# M0519AE_v1 register map
File version: 1.0
Registers are 32-bit, read-write, reset 0x0 unless marked. A register's access mark holds for its fields unless they carry their own. Offsets are from the block's base; [hi:lo] are bit positions; {n}, {i} and the like mark numbered series.

## FMC — FMC Register Map
Base 0x5000C000
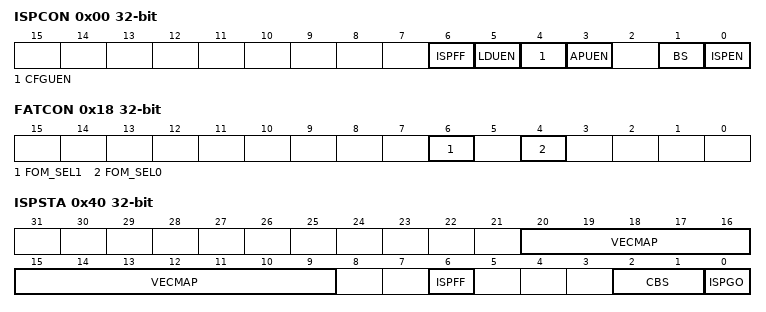
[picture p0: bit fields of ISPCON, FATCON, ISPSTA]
0x00 ISPCON (reset mask 0xFFFFFFF0) — ISP Control Register
  [6] ISPFF — ISP Fail Flag (Write Protect). This bit is set by hardware when a triggered ISP meets any of the following conditions: (1) APROM writes to itself if APUEN is set to 0. (2) LDROM writes to itself if LDUEN is set to 0. (3) CONFIG is erased/programmed if CFGUEN is set to 0. (4) Page Erase command at LOCK mode with ICE connection (5) Erase or Program command at brown-out detected (6) Destination address is illegal, such as over an available range. (7) Invalid ISP commands. Write 1 to clear this bit.
  [5] LDUEN — LDROM Update Enable Bit (Write Protect). LDROM update enable bit.
    0=LDROM cannot be updated; 1=LDROM can be updated when chip runs in APROM
  [4] CFGUEN — Config-bits Update Enable Bit (Write Protect)
    0=User Configuration cannot be updated; 1=User Configuration can be updated
  [3] APUEN — APROM Update Enable Bit (Write Protect)
    0=APROM cannot be updated when chip runs in APROM; 1=APROM can be updated when chip runs in APROM
  [1] BS — Boot Select (Write Protect). Set/clear this bit to select next booting from LDROM/APROM, respectively. This bit also functions as chip booting status flag, which can be used to check where chip booted from. This bit is initiated with the inversed value of CBS in Config0 after any reset is happened except CPU reset (RSTS_CPU is 1) or system reset (RSTS_SYS) is happened
    0=Boot from APROM; 1=Boot from LDROM
  [0] ISPEN — ISP Enable Bit (Write Protect). ISP function enable bit. Set this bit to enable ISP function.
    0=ISP function Disabled; 1=ISP function Enabled
0x04 ISPADR — ISP Address Register
  [31:0] ISPADR — ISP Address. The NuMicro M0519 Series has a maximum 32Kx32 (128 KB) of embedded Flash, which supports word program only. ISPADR[1:0] must be kept 00b for ISP operation.
0x08 ISPDAT — ISP Data Register
  [31:0] ISPDAT — ISP Data. Write data to this register before ISP program operation. Read data from this register after ISP read operation
0x0C ISPCMD — ISP Command Register
  [5:0] CMD — ISP Command. ISP command table is shown below: The other commands are invalid.
    0=FLASH Read; 4=Read Unique ID; 11=Read Company ID; 33=FLASH Program; 34=FLASH Page Erase; 46=Vector Remap
0x10 ISPTRG — ISP Trigger Control Register
  [0] ISPGO — ISP Start Trigger (Write Protect). Write 1 to start ISP operation and this bit will be cleared to 0 by hardware automatically when ISP operation is finished. This bit is the protected bit, It means programming this bit needs to write "59h", "16h", "88h" to address 0x5000_0100 to disable register protection. Refer to the register REGWRPROT at address GCR_BA+0x100. Note: To make sure ISP function has been finished before CPU goes ahead, ISB (Instruction Synchronization Barrier) instruction is used right after ISPGO (ISPTRG[0]) setting.
    0=ISP operation finished; 1=ISP progressed
0x14 DFBADR ro (reset mask 0xFFF00000) — Data Flash Base Address
  [31:0] DFBADR — Data Flash Base Address. This register indicates data flash start address. It is read only. For 128 KB flash memory device, the data flash size is defined by user configuration, register content is loaded from Config1 when chip is powered on but for 64 KB device, it is fixed at 0x0001_F000.
0x18 FATCON — Flash Access Time Control Register
  [6] FOM_SEL1 — Chip Frequency Optimization Mode Select (Write Protect)
  [4] FOM_SEL0 — Chip Frequency Optimization Mode Select (Write Protect)
0x40 ISPSTA (reset mask 0xFF0000F0) — ISP Status Register
  [20:9] VECMAP ro — Vector Page Mapping Address (Read Only). The current flash address space 0x0000_0000~0x0000_01FF is mapping to address {VECMAP[11:0], 9'h000} ~ {VECMAP[11:0], 9'h1FF} Note: vector map function only workable when IAP mode enabled
  [6] ISPFF — ISP Fail Flag (Write Protect). This bit is the mirror of ISPFF (ISPCON[6]), it needs to be cleared by writing 1 to ISPCON[6] or FMC_ISPSTA[6]. This bit is set by hardware when a triggered ISP meets any of the following conditions: (1) APROM writes to itself if APUEN is set to 0. (2) LDROM writes to itself if LDUEN is set to 0. (3) CONFIG is erased/programmed if CFGUEN is set to 0. (4) Page Erase command at LOCK mode with ICE connection (5) Erase or Program command at brown-out detected (6) Destination address is illegal, such as over an available range. (7) Invalid ISP commands. Write 1 to clear this bit.
  [2:1] CBS ro — Chip Boot Selection of CONFIG (Read Only)
    0=Boot from LDROM with IAP mode; 1=Boot from LDROM without IAP mode; 2=Boot from APROM with IAP mode; 3=Boot from APROM without IAP mode
  [0] ISPGO ro — ISP Start Trigger (Read Only). Write 1 to start ISP operation and this bit will be cleared to 0 by hardware automatically when ISP operation is finished. Note: This bit is the same with ISPTRG bit0
    0=ISP operation finished; 1=ISP operation progressed
